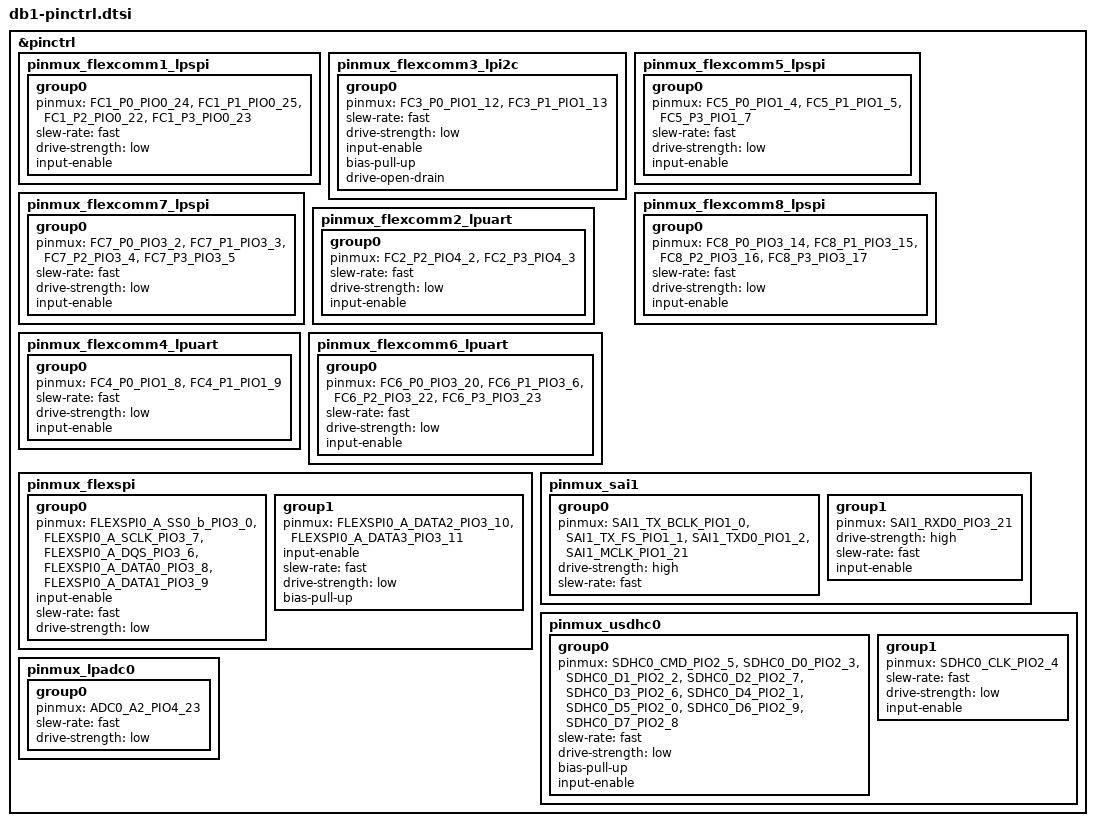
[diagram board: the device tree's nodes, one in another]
#include <nxp/mcx/MCXN947VDF-pinctrl.h>

&pinctrl {
	pinmux_flexcomm1_lpspi: pinmux_flexcomm1_lpspi {
		group0 {
			pinmux = <FC1_P0_PIO0_24>,
				<FC1_P1_PIO0_25>,
				<FC1_P2_PIO0_22>,
				<FC1_P3_PIO0_23>;
			slew-rate = "fast";
			drive-strength = "low";
			input-enable;
		};
	};

	pinmux_flexcomm3_lpi2c: pinmux_flexcomm3_lpi2c {
		group0 {
			pinmux = <FC3_P0_PIO1_12>,
				<FC3_P1_PIO1_13>;
			slew-rate = "fast";
			drive-strength = "low";
			input-enable;
			bias-pull-up;
			drive-open-drain;
		};
	};

	pinmux_flexcomm5_lpspi: pinmux_flexcomm5_lpspi {
		group0 {
			pinmux = <FC5_P0_PIO1_4>,
					 <FC5_P1_PIO1_5>,
					 <FC5_P3_PIO1_7>;
			slew-rate = "fast";
			drive-strength = "low";
			input-enable;
		};
	};

	pinmux_flexcomm7_lpspi: pinmux_flexcomm7_lpspi {
		group0 {
			pinmux = <FC7_P0_PIO3_2>,
					 <FC7_P1_PIO3_3>,
					 <FC7_P2_PIO3_4>,
					 <FC7_P3_PIO3_5>;
			slew-rate = "fast";
			drive-strength = "low";
			input-enable;
		};
	};

	pinmux_flexcomm8_lpspi: pinmux_flexcomm8_lpspi {
		group0 {
			pinmux = <FC8_P0_PIO3_14>,
					 <FC8_P1_PIO3_15>,
					 <FC8_P2_PIO3_16>,
					 <FC8_P3_PIO3_17>;
			slew-rate = "fast";
			drive-strength = "low";
			input-enable;
		};
	};

	pinmux_flexcomm2_lpuart: pinmux_flexcomm2_lpuart {
		group0 {
			pinmux = <FC2_P2_PIO4_2>,
				<FC2_P3_PIO4_3>;
			slew-rate = "fast";
			drive-strength = "low";
			input-enable;
		};
	};

	pinmux_flexcomm4_lpuart: pinmux_flexcomm4_lpuart {
		group0 {
			pinmux = <FC4_P0_PIO1_8>,
				<FC4_P1_PIO1_9>;
			slew-rate = "fast";
			drive-strength = "low";
			input-enable;
		};
	};

	pinmux_flexcomm6_lpuart: pinmux_flexcomm6_lpuart {
		group0 {
			pinmux = <FC6_P0_PIO3_20>,
				<FC6_P1_PIO3_6>,
				<FC6_P2_PIO3_22>,
				<FC6_P3_PIO3_23>;
			slew-rate = "fast";
			drive-strength = "low";
			input-enable;
		};
	};

	pinmux_flexspi: pinmux_flexspi {
		group0 {
			pinmux = <FLEXSPI0_A_SS0_b_PIO3_0>,
					<FLEXSPI0_A_SCLK_PIO3_7>,
					<FLEXSPI0_A_DQS_PIO3_6>,
					<FLEXSPI0_A_DATA0_PIO3_8>,
					<FLEXSPI0_A_DATA1_PIO3_9>;
			input-enable;
			slew-rate = "fast";
			drive-strength = "low";
		};
		group1 {
			pinmux = <FLEXSPI0_A_DATA2_PIO3_10>,
					<FLEXSPI0_A_DATA3_PIO3_11>;
			input-enable;
			slew-rate = "fast";
			drive-strength = "low";
			bias-pull-up;
		};
	};

	pinmux_sai1: pinmux_sai1 {
		group0 {
			pinmux = <SAI1_TX_BCLK_PIO1_0>,
				<SAI1_TX_FS_PIO1_1>,
				<SAI1_TXD0_PIO1_2>,
//				<SAI1_RX_BCLK_PIO3_18>, Also USER LED R on board 62-2
//				<SAI1_RX_FS_PIO3_19>, Also USER LED G on board 62-2
				<SAI1_MCLK_PIO1_21>;
			drive-strength = "high";
			slew-rate = "fast";
		};
		group1 {
			pinmux = <SAI1_RXD0_PIO3_21>;
			drive-strength = "high";
			slew-rate = "fast";
			input-enable;
		};
	};

	pinmux_usdhc0: pinmux_usdhc0 {
		group0 {
			pinmux = <SDHC0_CMD_PIO2_5>,
					 <SDHC0_D0_PIO2_3>,
					 <SDHC0_D1_PIO2_2>,
					 <SDHC0_D2_PIO2_7>,
					 <SDHC0_D3_PIO2_6>,
					 <SDHC0_D4_PIO2_1>,
					 <SDHC0_D5_PIO2_0>,
					 <SDHC0_D6_PIO2_9>,
					 <SDHC0_D7_PIO2_8>;
			slew-rate = "fast";
			drive-strength = "low";
			bias-pull-up;
			input-enable;
		};
		group1 {
			pinmux = <SDHC0_CLK_PIO2_4>;
			slew-rate = "fast";
			drive-strength = "low";
			input-enable;
		};
	};

	pinmux_lpadc0: pinmux_lpadc0 {
		group0 {
			pinmux = <ADC0_A2_PIO4_23>;
			slew-rate = "fast";
			drive-strength = "low";
		};
	};
};
